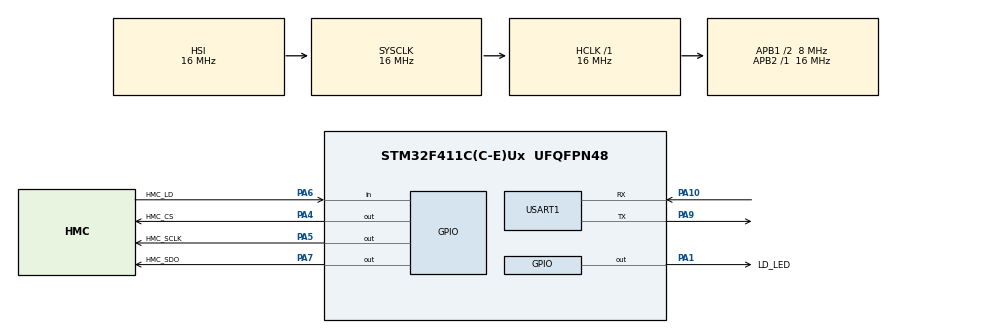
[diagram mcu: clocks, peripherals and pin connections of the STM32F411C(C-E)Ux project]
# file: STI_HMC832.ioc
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Mcu.Family=STM32F4
Mcu.Name=STM32F411C(C-E)Ux
Mcu.Package=UFQFPN48
NVIC.PriorityGroup=NVIC_PRIORITYGROUP_4
NVIC.USART1_IRQn=true\:0\:0\:false\:false\:true\:true\:true\:true
PA1.GPIO_Label=LD_LED
PA1.Signal=GPIO_Output
PA10.Mode=Asynchronous
PA10.Signal=USART1_RX
PA13.Mode=Serial_Wire
PA13.Signal=SYS_JTMS-SWDIO
PA14.Mode=Serial_Wire
PA14.Signal=SYS_JTCK-SWCLK
PA4.GPIO_Label=HMC_CS
PA4.Signal=GPIO_Output
PA5.GPIO_Label=HMC_SCLK
PA5.Signal=GPIO_Output
PA6.GPIO_Label=HMC_LD
PA6.Signal=GPIO_Input
PA7.GPIO_Label=HMC_SDO
PA7.Signal=GPIO_Output
PA9.Mode=Asynchronous
PA9.Signal=USART1_TX
ProjectManager.HeapSize=0x200
ProjectManager.StackSize=0x400
ProjectManager.TargetToolchain=MDK-ARM V5
RCC.48MHZClocksFreq_Value=32000000
RCC.AHBFreq_Value=16000000
RCC.APB1CLKDivider=RCC_HCLK_DIV2
RCC.APB1Freq_Value=8000000
RCC.APB1TimFreq_Value=16000000
RCC.APB2Freq_Value=16000000
RCC.APB2TimFreq_Value=16000000
RCC.CortexFreq_Value=16000000
RCC.HCLKFreq_Value=16000000
RCC.HSE_VALUE=25000000
RCC.HSI_VALUE=16000000
RCC.LSE_VALUE=32768
RCC.PLLM=8
RCC.PLLN=64
RCC.SYSCLKFreq_VALUE=16000000
RCC.VCOOutputFreq_Value=128000000
USART1.VirtualMode=VM_ASYNC
board=custom

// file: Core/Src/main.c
/* USER CODE BEGIN Header */
/**
  ******************************************************************************
  * @file           : main.c
  * @brief          : Main program body
  ******************************************************************************
  * @attention
  *
  * Copyright (c) 2024 STMicroelectronics.
  * All rights reserved.
  *
  * This software is licensed under terms that can be found in the LICENSE file
  * in the root directory of this software component.
  * If no LICENSE file comes with this software, it is provided AS-IS.
  *
  ******************************************************************************
  */
/* USER CODE END Header */
#include "main.h"
#include "usart.h"
#include "gpio.h"

/* USER CODE BEGIN Includes */
#include "HMC832.h"
#include "stdio.h"
/* USER CODE END Includes */

void SystemClock_Config(void);

/* USER CODE BEGIN 0 */
extern char RxBuffer[RXBUFSIZE];
extern uint8_t aRxBuffer;
extern uint8_t LOCKED;
extern uint8_t find_locked;
/* USER CODE END 0 */

int main(void)
{

  /* MCU Configuration--------------------------------------------------------*/

  /* Reset of all peripherals, Initializes the Flash interface and the Systick. */
  HAL_Init();

  /* Configure the system clock */
  SystemClock_Config();

  /* Initialize all configured peripherals */
  MX_GPIO_Init();
  MX_USART1_UART_Init();
  /* USER CODE BEGIN 2 */
	HAL_UART_Receive_IT(&huart1, (uint8_t *)&aRxBuffer, 1);
	HMC832_init();
	printf("HMC832 RF SYNTHESIZER IS ALREADY STARTED !\n");

  /* USER CODE END 2 */

  /* Infinite loop */
  while (1)
  {

    /* USER CODE BEGIN 3 */
		LOCKED= HAL_GPIO_ReadPin(GPIOA,HMC_LD_Pin);
		HAL_GPIO_WritePin(GPIOA,LD_LED_Pin,LOCKED);
		if(find_locked){
		if(LOCKED)printf("A1:LOCKED GOOD\n");
			find_locked=0;
		}
		//printf("hello\n");
  }
  /* USER CODE END 3 */
}

void SystemClock_Config(void)
{
  RCC_OscInitTypeDef RCC_OscInitStruct = {0};
  RCC_ClkInitTypeDef RCC_ClkInitStruct = {0};

  /** Configure the main internal regulator output voltage
  */
  __HAL_RCC_PWR_CLK_ENABLE();
  __HAL_PWR_VOLTAGESCALING_CONFIG(PWR_REGULATOR_VOLTAGE_SCALE1);

  /** Initializes the RCC Oscillators according to the specified parameters
  * in the RCC_OscInitTypeDef structure.
  */
  RCC_OscInitStruct.OscillatorType = RCC_OSCILLATORTYPE_HSI;
  RCC_OscInitStruct.HSIState = RCC_HSI_ON;
  RCC_OscInitStruct.HSICalibrationValue = RCC_HSICALIBRATION_DEFAULT;
  RCC_OscInitStruct.PLL.PLLState = RCC_PLL_NONE;
  if (HAL_RCC_OscConfig(&RCC_OscInitStruct) != HAL_OK)
  {
    Error_Handler();
  }

  /** Initializes the CPU, AHB and APB buses clocks
  */
  RCC_ClkInitStruct.ClockType = RCC_CLOCKTYPE_HCLK|RCC_CLOCKTYPE_SYSCLK
                              |RCC_CLOCKTYPE_PCLK1|RCC_CLOCKTYPE_PCLK2;
  RCC_ClkInitStruct.SYSCLKSource = RCC_SYSCLKSOURCE_HSI;
  RCC_ClkInitStruct.AHBCLKDivider = RCC_SYSCLK_DIV1;
  RCC_ClkInitStruct.APB1CLKDivider = RCC_HCLK_DIV2;
  RCC_ClkInitStruct.APB2CLKDivider = RCC_HCLK_DIV1;

  if (HAL_RCC_ClockConfig(&RCC_ClkInitStruct, FLASH_LATENCY_0) != HAL_OK)
  {
    Error_Handler();
  }
}

void Error_Handler(void)
{
  __disable_irq();
  while (1)
  {
  }
}
